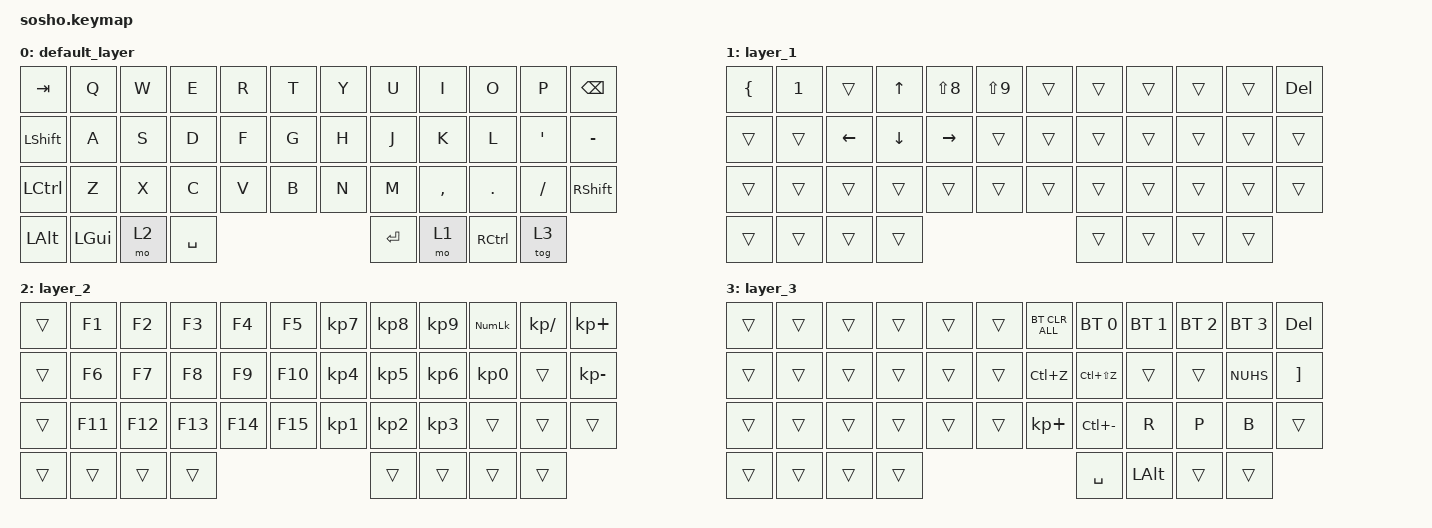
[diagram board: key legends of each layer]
/*
 * TH-601 (sosho) Keymap - Final Version
 */
#define ZMK_POINTING_DEFAULT_SCRL_VAL 150

#include <behaviors.dtsi>
#include <dt-bindings/zmk/bt.h>
#include <dt-bindings/zmk/keys.h>
#include <dt-bindings/zmk/pointing.h>
#include <dt-bindings/zmk/outputs.h>

&msc {
    time-to-max-speed-ms = <0>;
    acceleration-exponent = <0>;
};

/ {
    behaviors {
        msc_ec_l: sensor_rotation_scroll_L {
            compatible = "zmk,behavior-sensor-rotate-var";
            #sensor-binding-cells = <2>;
            bindings = <&msc>, <&msc>;
            tap-ms = <20>;
        };
        msc_ec_r: sensor_rotation_scroll_R {
            compatible = "zmk,behavior-sensor-rotate-var";
            #sensor-binding-cells = <2>;
            bindings = <&msc>, <&msc>;
            tap-ms = <20>;
        };
        ec_r_ps: sensor_rotation_ps_brush {
            compatible = "zmk,behavior-sensor-rotate";
            #sensor-binding-cells = <0>;
            bindings = <&kp NUHS>, <&kp RBKT>;
            tap-ms = <20>;
        };
    };
    combos {
        compatible = "zmk,combos";
        prioritize-longer-keys;
        combo_LCLK { timeout-ms = <50>; key-positions = <19 20>; bindings = <&mkp LCLK>; };
        combo_RCLK { timeout-ms = <50>; key-positions = <20 21>; bindings = <&mkp RCLK>; };
        combo_MCLK { timeout-ms = <90>; key-positions = <19 21>; bindings = <&mkp MCLK>; };
    };
    keymap {
        compatible = "zmk,keymap";
        default_layer {
            // Layer 0 (基本レイヤー)
            bindings = <
&kp TAB    &kp Q      &kp W      &kp E      &kp R      &kp T           &kp Y      &kp U      &kp I      &kp O      &kp P         &kp BSPC
&kp LSHFT  &kp A      &kp S      &kp D      &kp F      &kp G           &kp H      &kp J      &kp K      &kp L      &kp SQT       &kp MINUS
&kp LCTRL  &kp Z      &kp X      &kp C      &kp V      &kp B           &kp N      &kp M      &kp COMMA  &kp DOT    &kp FSLH      &kp RSHFT
&kp LALT   &kp LGUI   &mo 2      &kp SPACE                                        &kp RET    &mo 1      &kp RCTRL  &tog 3
            >;
            sensor-bindings = <&msc_ec_l SCRL_UP SCRL_DOWN &msc_ec_r SCRL_RIGHT SCRL_LEFT>;
        };
        layer_1 {
            // Layer 1 (記号・数字・矢印)
            bindings = <
&kp LBRC   &kp N1     &trans     &kp UP     &kp LS(N8) &kp LS(N9)      &trans     &trans     &trans     &trans     &trans        &kp DEL
&trans     &trans     &kp LEFT   &kp DOWN   &kp RIGHT  &trans          &trans     &trans     &trans     &trans     &trans        &trans
&trans     &trans     &trans     &trans     &trans     &trans          &trans     &trans     &trans     &trans     &trans        &trans
&trans     &trans     &trans     &trans                                           &trans     &trans     &trans     &trans
            >;
            sensor-bindings = <&msc_ec_l SCRL_UP SCRL_DOWN &msc_ec_r SCRL_RIGHT SCRL_LEFT>;
        };
        layer_2 {
            // Layer 2 (ファンクションキー・テンキー)
            bindings = <
&trans     &kp F1     &kp F2     &kp F3     &kp F4     &kp F5          &kp KP_N7  &kp KP_N8  &kp KP_N9  &kp KP_NUM &kp KP_DIVIDE &kp KP_PLUS
&trans     &kp F6     &kp F7     &kp F8     &kp F9     &kp F10         &kp KP_N4  &kp KP_N5  &kp KP_N6  &kp KP_N0  &trans        &kp KP_MINUS
&trans     &kp F11    &kp F12    &kp F13    &kp F14    &kp F15         &kp KP_N1  &kp KP_N2  &kp KP_N3  &trans     &trans        &trans
&trans     &trans     &trans     &trans                                           &trans     &trans     &trans     &trans
            >;
            sensor-bindings = <&msc_ec_l SCRL_UP SCRL_DOWN &msc_ec_r SCRL_RIGHT SCRL_LEFT>;
        };
        layer_3 {
            // Layer 3 (Bluetooth・マクロ)
            bindings = <
&trans     &trans     &trans     &trans     &trans     &trans          &bt BT_CLR_ALL &bt BT_SEL 0 &bt BT_SEL 1 &bt BT_SEL 2 &bt BT_SEL 3 &kp DEL
&trans     &trans     &trans     &trans     &trans     &trans          &kp LC(Z)      &kp LC(LS(Z))&trans       &trans       &kp NUHS     &kp RBKT
&trans     &trans     &trans     &trans     &trans     &trans          &kp KP_PLUS    &kp LC(MINUS)&kp R        &kp P        &kp B        &trans
&trans     &trans     &trans     &trans                                               &kp SPACE    &kp LALT     &trans       &trans
            >;
            sensor-bindings = <&msc_ec_l SCRL_UP SCRL_DOWN &ec_r_ps>;
        };
    };
};
